# STM32H73x register map
File version: 1.0
CPU: CM7 r0p1, little endian, MPU, FPU, 4 interrupt priority bits
Registers are 32-bit, read-write, reset 0x0 unless marked. A register's access mark holds for its fields unless they carry their own. Offsets are from the block's base; [hi:lo] are bit positions; {n}, {i} and the like mark numbered series; 'fields as' and 'values as' point back to an identical list.

## HSEM
Base 0x58026400
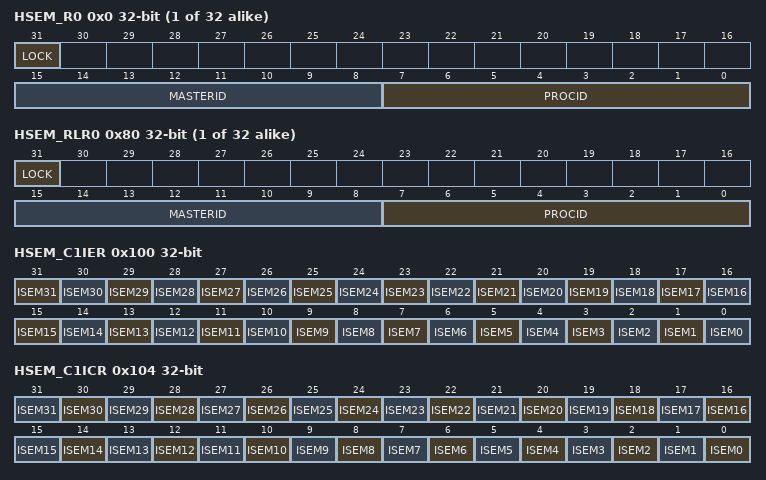
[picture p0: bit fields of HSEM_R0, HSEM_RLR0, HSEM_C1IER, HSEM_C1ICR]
{0x0+4i} HSEM_R{i} (i=0..31) — HSEM register HSEM_R0 HSEM_R31
  [31] LOCK — Lock indication
  [15:8] MASTERID — Semaphore MasterID
  [7:0] PROCID — Semaphore ProcessID
{0x80+4i} HSEM_RLR{i} ro (i=0..31) — HSEM Read lock register
  fields as HSEM_R0
0x100 HSEM_C1IER — HSEM Interrupt enable register
  [31] ISEM31 — Interrupt(N) semaphore n enable bit.
  [n] ISEM{n} (n=0..30) — Interrupt semaphore n enable bit
0x104 HSEM_C1ICR ro — HSEM Interrupt clear register
  [n] ISEM{n} (n=0..31) — Interrupt(N) semaphore n clear bit
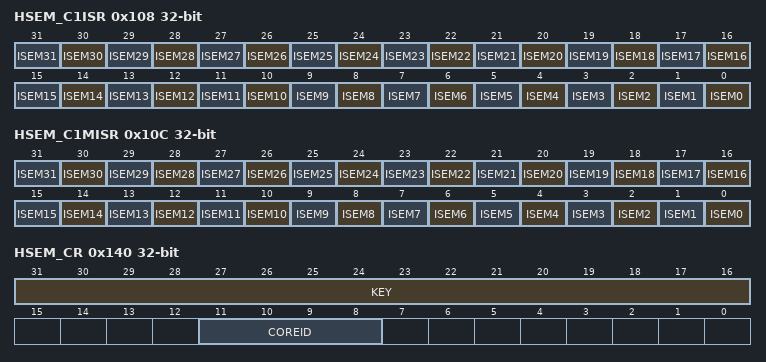
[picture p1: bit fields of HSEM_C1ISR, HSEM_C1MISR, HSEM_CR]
0x108 HSEM_C1ISR ro — HSEM Interrupt status register
  [n] ISEM{n} (n=0..31) — Interrupt(N) semaphore n status bit before enable (mask)
0x10C HSEM_C1MISR ro — HSEM Masked interrupt status register
  [n] ISEM{n} (n=0..31) — masked interrupt(N) semaphore n status bit after enable (mask)
0x140 HSEM_CR — HSEM Clear register
  [31:16] KEY — Semaphore clear Key
  [11:8] COREID — MasterID of semaphores to be cleared
0x144 HSEM_KEYR — HSEM Interrupt clear register
  [31:16] KEY — Semaphore Clear Key

## OctoSPII_O_Manager
Base 0x5200B400
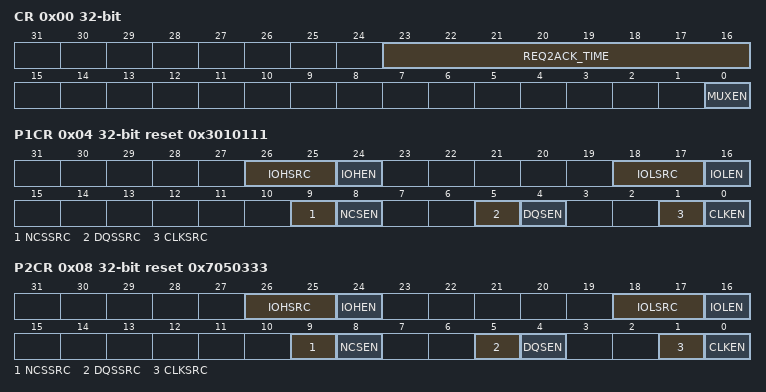
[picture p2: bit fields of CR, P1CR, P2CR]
0x00 CR — OctoSPI IO Manager Control Register
  [23:16] REQ2ACK_TIME — REQ to ACK Time
  [0] MUXEN — Multiplexed mode Enable
0x04 P1CR reset 0x3010111 — OctoSPI IO Manager Port 1 configuration register
  [26:25] IOHSRC
  [24] IOHEN
  [18:17] IOLSRC
  [16] IOLEN
  [9] NCSSRC
  [8] NCSEN
  [5] DQSSRC
  [4] DQSEN
  [1] CLKSRC — CLK/CLKn Source for Port n
  [0] CLKEN — CLK/CLKn Enable for Port n
0x08 P2CR reset 0x7050333 — OctoSPI IO Manager Port 2 configuration register
  [26:25] IOHSRC, [24] IOHEN, [18:17] IOLSRC, [16] IOLEN, [9] NCSSRC, [8] NCSEN, [5] DQSSRC, [4] DQSEN, [1] CLKSRC, [0] CLKEN

## DELAY_Block_SDMMC1
Base 0x52008000
Same registers: DELAY_Block_SDMMC2 0x48022800, Delay_Block_OCTOSPI1 0x52006000, Delay_Block_OCTOSPI2 0x5200B000
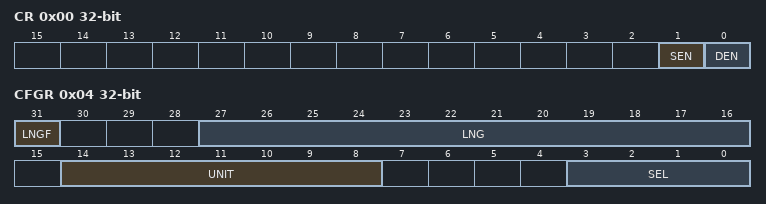
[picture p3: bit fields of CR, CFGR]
0x00 CR — DLYB control register
  [1] SEN — Sampler length enable bit
  [0] DEN — Delay block enable bit
0x04 CFGR — DLYB configuration register
  [31] LNGF — Length valid flag
  [27:16] LNG — Delay line length value
  [14:8] UNIT — Delay Defines the delay of a Unit delay cell
  [3:0] SEL — Select the phase for the Output clock

## RNG
Base 0x48021800
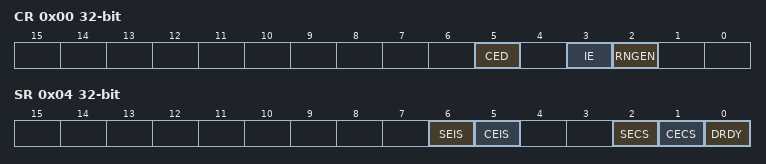
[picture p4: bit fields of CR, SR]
0x00 CR — RNG control register
  [5] CED — Clock error detection Note: The clock error detection can be used only when ck_rc48 or ck_pll1_q (ck_pll1_q = 48MHz) source is selected otherwise, CED bit must be equal to 1. The clock error detection cannot be enabled nor disabled on the fly when RNG peripheral is enabled, to enable or disable CED the RNG must be disabled.
  [3] IE — Interrupt enable
  [2] RNGEN — Random number generator enable
0x04 SR access per field — RNG status register
  [6] SEIS rw — Seed error interrupt status This bit is set at the same time as SECS. It is cleared by writing it to 0. ** More than 64 consecutive bits at the same value (0 or 1) ** More than 32 consecutive alternances of 0 and 1 (0101010101...01) An interrupt is pending if IE = 1 in the RNG_CR register.
  [5] CEIS rw — Clock error interrupt status This bit is set at the same time as CECS. It is cleared by writing it to 0. An interrupt is pending if IE = 1 in the RNG_CR register. Note: This bit is meaningless if CED (Clock error detection) bit in RNG_CR is equal to 1.
  [2] SECS ro — Seed error current status ** More than 64 consecutive bits at the same value (0 or 1) ** More than 32 consecutive alternances of 0 and 1 (0101010101...01)
  [1] CECS ro — Clock error current status Note: This bit is meaningless if CED (Clock error detection) bit in RNG_CR is equal to 1.
  [0] DRDY ro — Data ready Note: If IE=1 in RNG_CR, an interrupt is generated when DRDY=1. It can rise when the peripheral is disabled. When the output buffer becomes empty (after reading RNG_DR), this bit returns to 0 until a new random value is generated.
0x08 DR ro — The RNG_DR register is a read-only register that delivers a 32-bit random value when read. The content of this register is valid when DRDY= 1, even if RNGEN=0.
  [31:0] RNDATA — Random data 32-bit random data which are valid when DRDY=1.
